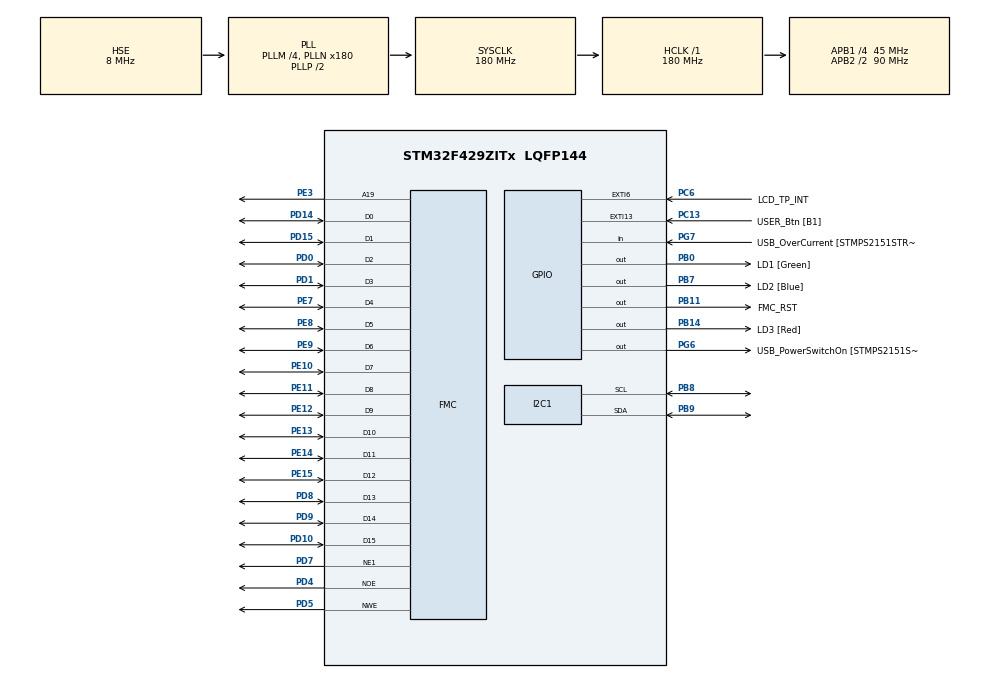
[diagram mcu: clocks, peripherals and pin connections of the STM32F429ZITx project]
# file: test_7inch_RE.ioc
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DMA2D.ColorMode=DMA2D_OUTPUT_RGB565
FMC.AddressSetupTime1=6
FMC.BusTurnAroundDuration1=0
FMC.DataSetupTime1=6
I2C1.I2C_Mode=I2C_Fast
Mcu.Family=STM32F4
Mcu.Name=STM32F429ZITx
Mcu.Package=LQFP144
Mcu.UserConstants=VSync_TIM_Period,16000-1;VSync_TIM_Prescaler,180/2-1
NVIC.DMA2D_IRQn=true\:0\:0\:false\:false\:true\:true\:true
NVIC.EXTI15_10_IRQn=true\:0\:0\:false\:false\:true\:true\:true
NVIC.EXTI9_5_IRQn=true\:0\:0\:false\:false\:true\:true\:true
NVIC.I2C1_EV_IRQn=true\:0\:0\:false\:false\:true\:true\:true
NVIC.PriorityGroup=NVIC_PRIORITYGROUP_4
NVIC.TIM6_DAC_IRQn=true\:0\:0\:false\:false\:true\:true\:true
NVIC.TIM7_IRQn=true\:0\:0\:false\:false\:true\:true\:true
PA1.GPIO_Label=RMII_REF_CLK [LAN8742A-CZ-TR_REFCLK0]
PA1.Signal=ETH_REF_CLK
PA10.GPIO_Label=USB_ID
PA10.Signal=USB_OTG_FS_ID
PA11.GPIO_Label=USB_DM
PA11.Signal=USB_OTG_FS_DM
PA12.GPIO_Label=USB_DP
PA12.Signal=USB_OTG_FS_DP
PA13.GPIO_Label=TMS
PA13.Mode=Serial_Wire
PA13.Signal=SYS_JTMS-SWDIO
PA14.GPIO_Label=TCK
PA14.Mode=Serial_Wire
PA14.Signal=SYS_JTCK-SWCLK
PA2.GPIO_Label=RMII_MDIO [LAN8742A-CZ-TR_MDIO]
PA2.Signal=ETH_MDIO
PA8.GPIO_Label=USB_SOF [TP1]
PA8.Signal=USB_OTG_FS_SOF
PA9.GPIO_Label=USB_VBUS
PA9.Signal=USB_OTG_FS_VBUS
PB0.GPIO_Label=LD1 [Green]
PB0.Signal=GPIO_Output
PB11.GPIO_Label=FMC_RST
PB11.Signal=GPIO_Output
PB14.GPIO_Label=LD3 [Red]
PB14.Signal=GPIO_Output
PB7.GPIO_Label=LD2 [Blue]
PB7.Signal=GPIO_Output
PB8.Mode=I2C
PB8.Signal=I2C1_SCL
PB9.Mode=I2C
PB9.Signal=I2C1_SDA
PC1.GPIO_Label=RMII_MDC [LAN8742A-CZ-TR_MDC]
PC1.Signal=ETH_MDC
PC13.GPIO_Label=USER_Btn [B1]
PC13.Signal=GPXTI13
PC14/OSC32_IN.Signal=RCC_OSC32_IN
PC15/OSC32_OUT.Signal=RCC_OSC32_OUT
PC6.GPIO_Label=LCD_TP_INT
PC6.GPIO_ModeDefaultEXTI=GPIO_MODE_IT_FALLING
PC6.GPIO_PuPd=GPIO_NOPULL
PC6.Signal=GPXTI6
PD0.Signal=FMC_D2_DA2
PD1.Signal=FMC_D3_DA3
PD10.Signal=FMC_D15_DA15
PD14.Signal=FMC_D0_DA0
PD15.Signal=FMC_D1_DA1
PD4.Signal=FMC_NOE
PD5.Signal=FMC_NWE
PD7.Mode=NorPsramChipSelect1_1
PD7.Signal=FMC_NE1
PD8.Signal=FMC_D13_DA13
PD9.Signal=FMC_D14_DA14
PE10.Signal=FMC_D7_DA7
PE11.Signal=FMC_D8_DA8
PE12.Signal=FMC_D9_DA9
PE13.Signal=FMC_D10_DA10
PE14.Signal=FMC_D11_DA11
PE15.Signal=FMC_D12_DA12
PE3.Signal=FMC_A19
PE7.Signal=FMC_D4_DA4
PE8.Signal=FMC_D5_DA5
PE9.Signal=FMC_D6_DA6
PG6.GPIO_Label=USB_PowerSwitchOn [STMPS2151STR_EN]
PG6.Signal=GPIO_Output
PG7.GPIO_Label=USB_OverCurrent [STMPS2151STR_FAULT]
PG7.Signal=GPIO_Input
PH0/OSC_IN.GPIO_Label=MCO [STM32F103CBT6_PA8]
PH0/OSC_IN.Mode=HSE-External-Oscillator
PH0/OSC_IN.Signal=RCC_OSC_IN
PH1/OSC_OUT.Mode=HSE-External-Oscillator
PH1/OSC_OUT.Signal=RCC_OSC_OUT
ProjectManager.HeapSize=0x200
ProjectManager.StackSize=0x4000
ProjectManager.TargetToolchain=STM32CubeIDE
RCC.48MHZClocksFreq_Value=90000000
RCC.AHBFreq_Value=180000000
RCC.APB1CLKDivider=RCC_HCLK_DIV4
RCC.APB1Freq_Value=45000000
RCC.APB1TimFreq_Value=90000000
RCC.APB2CLKDivider=RCC_HCLK_DIV2
RCC.APB2Freq_Value=90000000
RCC.APB2TimFreq_Value=180000000
RCC.CortexFreq_Value=180000000
RCC.HCLKFreq_Value=180000000
RCC.HSE_VALUE=8000000
RCC.HSI_VALUE=16000000
RCC.LSE_VALUE=32768
RCC.PLLM=4
RCC.PLLMUL=RCC_PLL_MUL9
RCC.PLLN=180
RCC.PLLSourceVirtual=RCC_PLLSOURCE_HSE
RCC.PRESCALERUSB=RCC_USBCLKSOURCE_PLL_DIV1_5
RCC.SYSCLKFreq_VALUE=180000000
RCC.SYSCLKSource=RCC_SYSCLKSOURCE_PLLCLK
RCC.SYSCLKSourceVirtual=RCC_SYSCLKSOURCE_PLLCLK
RCC.USBFreq_Value=48000000
RCC.VCOOutputFreq_Value=360000000
SH.FMC_A19.0=FMC_A19,A19_1
SH.FMC_D0_DA0.0=FMC_D0,16b-d1
SH.FMC_D10_DA10.0=FMC_D10,16b-d1
SH.FMC_D11_DA11.0=FMC_D11,16b-d1
SH.FMC_D12_DA12.0=FMC_D12,16b-d1
SH.FMC_D13_DA13.0=FMC_D13,16b-d1
SH.FMC_D14_DA14.0=FMC_D14,16b-d1
SH.FMC_D15_DA15.0=FMC_D15,16b-d1
SH.FMC_D1_DA1.0=FMC_D1,16b-d1
SH.FMC_D2_DA2.0=FMC_D2,16b-d1
SH.FMC_D3_DA3.0=FMC_D3,16b-d1
SH.FMC_D4_DA4.0=FMC_D4,16b-d1
SH.FMC_D5_DA5.0=FMC_D5,16b-d1
SH.FMC_D6_DA6.0=FMC_D6,16b-d1
SH.FMC_D7_DA7.0=FMC_D7,16b-d1
SH.FMC_D8_DA8.0=FMC_D8,16b-d1
SH.FMC_D9_DA9.0=FMC_D9,16b-d1
SH.FMC_NOE.0=FMC_NOE,Lcd1
SH.FMC_NWE.0=FMC_NWE,Lcd1
STMicroelectronics.X-CUBE-TOUCHGFX.4.15.0.ApplicationCcGraphicsJjApplication=TouchGFXOoGenerator
STMicroelectronics.X-CUBE-TOUCHGFX.4.15.0.tgfx_block_size=200*20
STMicroelectronics.X-CUBE-TOUCHGFX.4.15.0.tgfx_buffering_strategy=Partial
STMicroelectronics.X-CUBE-TOUCHGFX.4.15.0.tgfx_custom_height=480
STMicroelectronics.X-CUBE-TOUCHGFX.4.15.0.tgfx_custom_width=800
STMicroelectronics.X-CUBE-TOUCHGFX.4.15.0.tgfx_hardware_accelerator=dma_2d
STMicroelectronics.X-CUBE-TOUCHGFX.4.15.0.tgfx_number_of_blocks=20
TIM6.Period=1000-1
TIM6.Prescaler=180/2-1
TIM7.Period=VSync_TIM_Period
TIM7.Prescaler=VSync_TIM_Prescaler
VP_CRC_VS_CRC.Mode=CRC_Activate
VP_DMA2D_VS_DMA2D.Mode=DMA2D_Activate
VP_STMicroelectronics.X-CUBE-TOUCHGFX_VS_GraphicsJjApplication_4.15.0.Mode=GraphicsJjApplication
VP_TIM6_VS_ClockSourceINT.Mode=Enable_Timer
VP_TIM7_VS_ClockSourceINT.Mode=Enable_Timer
board=NUCLEO-F429ZI

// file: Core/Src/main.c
/* USER CODE BEGIN Header */
/**
  ******************************************************************************
  * @file           : main.c
  * @brief          : Main program body
  ******************************************************************************
  * @attention
  *
  * <h2><center>&copy; Copyright (c) 2020 STMicroelectronics.
  * All rights reserved.</center></h2>
  *
  * This software component is licensed by ST under Ultimate Liberty license
  * SLA0044, the "License"; You may not use this file except in compliance with
  * the License. You may obtain a copy of the License at:
  *                             www.st.com/SLA0044
  *
  ******************************************************************************
  */
/* USER CODE END Header */
#include "main.h"
#include "crc.h"
#include "dma2d.h"
#include "i2c.h"
#include "tim.h"
#include "gpio.h"
#include "fmc.h"
#include "app_touchgfx.h"

/* USER CODE BEGIN Includes */
#include "lcd.h"
#include "lcd_TP.h"
/* USER CODE END Includes */

void SystemClock_Config(void);
/* USER CODE BEGIN PFP */
extern void DisplayDriver_TransferCompleteCallback();
/* USER CODE END PFP */

int main(void)
{

  /* MCU Configuration--------------------------------------------------------*/

  /* Reset of all peripherals, Initializes the Flash interface and the Systick. */
  HAL_Init();

  /* Configure the system clock */
  SystemClock_Config();

  /* Initialize all configured peripherals */
  MX_GPIO_Init();
  MX_FMC_Init();
  MX_CRC_Init();
  MX_DMA2D_Init();
  MX_TIM7_Init();
  MX_TIM6_Init();
  MX_I2C1_Init();
  MX_TouchGFX_Init();
  /* USER CODE BEGIN 2 */
  LCD_init();
  LCD_TP_init();
  HAL_TIM_Base_Start_IT(&htim7);
  HAL_TIM_Base_Start_IT(&htim6);
  /* USER CODE END 2 */

  /* Infinite loop */
  while (1)
  {

  MX_TouchGFX_Process();
  }
}

void SystemClock_Config(void)
{
  RCC_OscInitTypeDef RCC_OscInitStruct = {0};
  RCC_ClkInitTypeDef RCC_ClkInitStruct = {0};

  /** Configure the main internal regulator output voltage
  */
  __HAL_RCC_PWR_CLK_ENABLE();
  __HAL_PWR_VOLTAGESCALING_CONFIG(PWR_REGULATOR_VOLTAGE_SCALE1);
  /** Initializes the RCC Oscillators according to the specified parameters
  * in the RCC_OscInitTypeDef structure.
  */
  RCC_OscInitStruct.OscillatorType = RCC_OSCILLATORTYPE_HSE;
  RCC_OscInitStruct.HSEState = RCC_HSE_ON;
  RCC_OscInitStruct.PLL.PLLState = RCC_PLL_ON;
  RCC_OscInitStruct.PLL.PLLSource = RCC_PLLSOURCE_HSE;
  RCC_OscInitStruct.PLL.PLLM = 4;
  RCC_OscInitStruct.PLL.PLLN = 180;
  RCC_OscInitStruct.PLL.PLLP = RCC_PLLP_DIV2;
  RCC_OscInitStruct.PLL.PLLQ = 4;
  if (HAL_RCC_OscConfig(&RCC_OscInitStruct) != HAL_OK)
  {
    Error_Handler();
  }
  /** Activate the Over-Drive mode
  */
  if (HAL_PWREx_EnableOverDrive() != HAL_OK)
  {
    Error_Handler();
  }
  /** Initializes the CPU, AHB and APB buses clocks
  */
  RCC_ClkInitStruct.ClockType = RCC_CLOCKTYPE_HCLK|RCC_CLOCKTYPE_SYSCLK
                              |RCC_CLOCKTYPE_PCLK1|RCC_CLOCKTYPE_PCLK2;
  RCC_ClkInitStruct.SYSCLKSource = RCC_SYSCLKSOURCE_PLLCLK;
  RCC_ClkInitStruct.AHBCLKDivider = RCC_SYSCLK_DIV1;
  RCC_ClkInitStruct.APB1CLKDivider = RCC_HCLK_DIV4;
  RCC_ClkInitStruct.APB2CLKDivider = RCC_HCLK_DIV2;

  if (HAL_RCC_ClockConfig(&RCC_ClkInitStruct, FLASH_LATENCY_5) != HAL_OK)
  {
    Error_Handler();
  }
}

/* USER CODE BEGIN 4 */
int touchgfxDisplayDriverTransmitActive(){
	return LCD_isBusy(0x50, 0x80);
}
void touchgfxDisplayDriverTransmitBlock(const uint8_t* pixels, uint16_t x, uint16_t y, uint16_t w, uint16_t h){
	LCD_drawBuffer((uint16_t*)pixels, x, y, w, h);
	DisplayDriver_TransferCompleteCallback();
}
/* USER CODE END 4 */

void Error_Handler(void)
{
}

/************************ (C) COPYRIGHT STMicroelectronics *****END OF FILE****/
